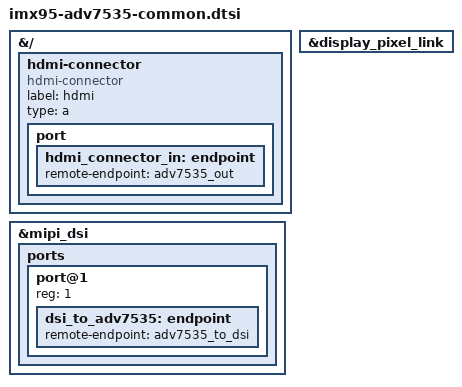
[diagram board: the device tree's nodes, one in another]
// SPDX-License-Identifier: (GPL-2.0+ OR MIT)
/*
 * Copyright 2026 NXP
 */

/dts-v1/;
/plugin/;

&{/} {
	hdmi-connector {
		compatible = "hdmi-connector";
		label = "hdmi";
		type = "a";

		port {
			hdmi_connector_in: endpoint {
				remote-endpoint = <&adv7535_out>;
			};
		};
	};
};

&display_pixel_link {
	status = "okay";
};

&mipi_dsi {
	status = "okay";

	ports {
		#address-cells = <1>;
		#size-cells = <0>;

		port@1 {
			reg = <1>;

			dsi_to_adv7535: endpoint {
				remote-endpoint = <&adv7535_to_dsi>;
			};
		};
	};
};
